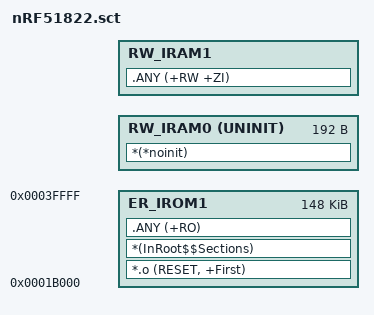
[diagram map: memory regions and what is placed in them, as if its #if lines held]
;WITHOUT SOFTDEVICE:
;LR_IROM1 0x00000000 0x00040000  {
;  ER_IROM1 0x00000000 0x00040000  {
;   *.o (RESET, +First)
;   *(InRoot$$Sections)
;   .ANY (+RO)
;  }
;  RW_IRAM1 0x20000000 0x00008000  {
;   .ANY (+RW +ZI)
;  }
;}
;
;WITH SOFTDEVICE:

#if defined(MBED_CONF_SD_RAM_ALLOC)
  #define APP_RAM_BASE (0x20000000 + MBED_CONF_SD_RAM_ALLOC)
#else
  #define APP_RAM_BASE 0x20002ef8
#endif

LR_IROM1 0x1B000 0x0025000  {
  ER_IROM1 0x1B000 0x0025000  {
   *.o (RESET, +First)
   *(InRoot$$Sections)
   .ANY (+RO)
  }
  RW_IRAM0 APP_RAM_BASE UNINIT 0x000000c0  { ;no init section
        *(*noinit)
  }
  RW_IRAM1 (APP_RAM_BASE + 0xC0) (0x20008000 - APP_RAM_BASE - 0xC0)  {
   .ANY (+RW +ZI)
  }
}
